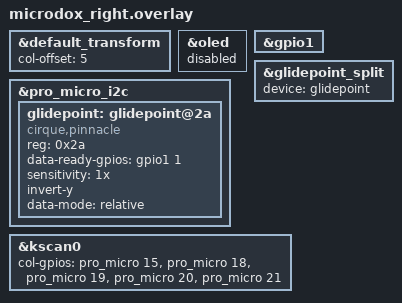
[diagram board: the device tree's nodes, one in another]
/*
 * Copyright (c) 2020 The ZMK Contributors
 *
 * SPDX-License-Identifier: MIT
 */

#include "microdox.dtsi"
#include "microdox_cirque.dtsi"

&default_transform {
    col-offset = <5>;
};

&oled {
    status = "disabled";
};

&gpio1 {
    status = "okay";
};

&pro_micro_i2c {
  status = "okay";

  glidepoint: glidepoint@2a {
    compatible = "cirque,pinnacle";
    reg = <0x2a>;

    data-ready-gpios = <&gpio1 1 (GPIO_ACTIVE_HIGH)>; // 1 and high works, low does not

    sensitivity = "1x"; // keep this on 1x, doesn't reach to edges of trackpad otherwise
    invert-y;
    data-mode = "relative"; // needs to be relative, absolute won't work
    // primary-tap-enable; // register clicks, this is off and using the keyboard because its not registering taps correctly, too sensitive? unable to drag. Logs help here
    // idle-packets-count = <5>; // TODO: need to check this
  };
};

&glidepoint_split {
  device = <&glidepoint>;
};

&kscan0 {
    col-gpios
        = <&pro_micro 15 GPIO_ACTIVE_HIGH>
        , <&pro_micro 18 GPIO_ACTIVE_HIGH>
        , <&pro_micro 19 GPIO_ACTIVE_HIGH>
        , <&pro_micro 20 GPIO_ACTIVE_HIGH>
        , <&pro_micro 21 GPIO_ACTIVE_HIGH>
        ;
};
